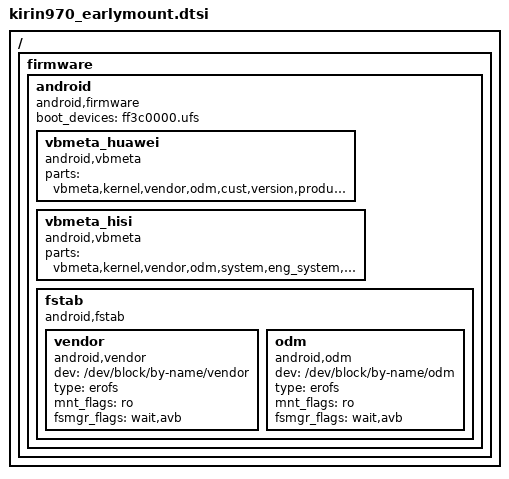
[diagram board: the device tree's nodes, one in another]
/{
	firmware {
		android {
			compatible = "android,firmware";
			boot_devices ="ff3c0000.ufs";
			vbmeta_huawei {
				compatible = "android,vbmeta";
				parts = "vbmeta,kernel,vendor,odm,cust,version,product,system,eng_system,eng_vendor,preload,patch,preas,preavs";
			};
			vbmeta_hisi {
				compatible = "android,vbmeta";
				parts = "vbmeta,kernel,vendor,odm,system,eng_system,eng_vendor";
			};
			fstab {
				compatible = "android,fstab";
				vendor {
					compatible = "android,vendor";
					dev = "/dev/block/by-name/vendor";
					type = "erofs";
					mnt_flags = "ro";
					fsmgr_flags = "wait,avb";
					status = "ok";
				};
				odm {
					compatible = "android,odm";
					dev = "/dev/block/by-name/odm";
					type = "erofs";
					mnt_flags = "ro";
					fsmgr_flags = "wait,avb";
					status = "ok";
				};
			};
		};
	};
};
